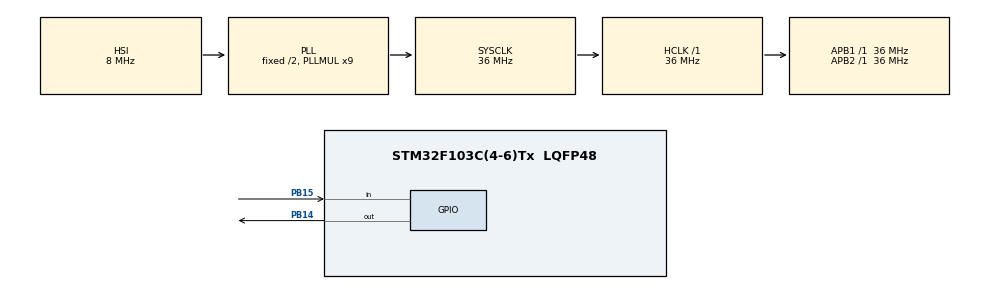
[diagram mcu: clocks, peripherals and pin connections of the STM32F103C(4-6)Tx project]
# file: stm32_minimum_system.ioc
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Mcu.Family=STM32F1
Mcu.Name=STM32F103C(4-6)Tx
Mcu.Package=LQFP48
NVIC.PriorityGroup=NVIC_PRIORITYGROUP_4
PB14.GPIO_PuPd=GPIO_NOPULL
PB14.GPIO_Speed=GPIO_SPEED_FREQ_LOW
PB14.PinState=GPIO_PIN_SET
PB14.Signal=GPIO_Output
PB15.GPIO_PuPd=GPIO_PULLUP
PB15.Signal=GPIO_Input
ProjectManager.HeapSize=0x200
ProjectManager.StackSize=0x400
ProjectManager.TargetToolchain=MDK-ARM V5
RCC.AHBFreq_Value=36000000
RCC.APB1Freq_Value=36000000
RCC.APB1TimFreq_Value=36000000
RCC.APB2Freq_Value=36000000
RCC.APB2TimFreq_Value=36000000
RCC.HCLKFreq_Value=36000000
RCC.PLLMUL=RCC_PLL_MUL9
RCC.SYSCLKFreq_VALUE=36000000
RCC.SYSCLKSource=RCC_SYSCLKSOURCE_PLLCLK
RCC.USBFreq_Value=36000000
VP_SYS_VS_ND.Mode=No_Debug
board=custom

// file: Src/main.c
/* USER CODE BEGIN Header */
/**
  ******************************************************************************
  * @file           : main.c
  * @brief          : Main program body
  ******************************************************************************
  * @attention
  *
  * <h2><center>&copy; Copyright (c) 2019 STMicroelectronics.
  * All rights reserved.</center></h2>
  *
  * This software component is licensed by ST under BSD 3-Clause license,
  * the "License"; You may not use this file except in compliance with the
  * License. You may obtain a copy of the License at:
  *                        opensource.org/licenses/BSD-3-Clause
  *
  ******************************************************************************
  */
/* USER CODE END Header */

#include "main.h"

/* USER CODE BEGIN PD */
#define LED_OFF HAL_GPIO_WritePin(GPIOB, GPIO_PIN_14, GPIO_PIN_SET);  //端口置1
#define LED_ON HAL_GPIO_WritePin(GPIOB, GPIO_PIN_14, GPIO_PIN_RESET);  //端口置0
/* USER CODE END PD */

void SystemClock_Config(void);
static void MX_GPIO_Init(void);

int main(void)
{

  /* MCU Configuration--------------------------------------------------------*/

  /* Reset of all peripherals, Initializes the Flash interface and the Systick. */
  HAL_Init();

  /* Configure the system clock */
  SystemClock_Config();

  /* Initialize all configured peripherals */
  MX_GPIO_Init();

  /* Infinite loop */
  while (1)
  {
    if (HAL_GPIO_ReadPin(GPIOB,GPIO_PIN_15) == 0)
    {
      HAL_Delay(10);  //延迟10ms
      if (HAL_GPIO_ReadPin(GPIOB,GPIO_PIN_15) == 0)
        LED_ON;
    }
    if (HAL_GPIO_ReadPin(GPIOB,GPIO_PIN_15) != 0)
    {
      HAL_Delay(10);  //延迟10ms
      if (HAL_GPIO_ReadPin(GPIOB,GPIO_PIN_15) != 0)
        LED_OFF;
    }
  }
}

void SystemClock_Config(void)
{
  RCC_OscInitTypeDef RCC_OscInitStruct = {0};
  RCC_ClkInitTypeDef RCC_ClkInitStruct = {0};

  /** Initializes the CPU, AHB and APB busses clocks
  */
  RCC_OscInitStruct.OscillatorType = RCC_OSCILLATORTYPE_HSI;
  RCC_OscInitStruct.HSIState = RCC_HSI_ON;
  RCC_OscInitStruct.HSICalibrationValue = RCC_HSICALIBRATION_DEFAULT;
  RCC_OscInitStruct.PLL.PLLState = RCC_PLL_ON;
  RCC_OscInitStruct.PLL.PLLSource = RCC_PLLSOURCE_HSI_DIV2;
  RCC_OscInitStruct.PLL.PLLMUL = RCC_PLL_MUL9;
  if (HAL_RCC_OscConfig(&RCC_OscInitStruct) != HAL_OK)
  {
    Error_Handler();
  }
  /** Initializes the CPU, AHB and APB busses clocks
  */
  RCC_ClkInitStruct.ClockType = RCC_CLOCKTYPE_HCLK|RCC_CLOCKTYPE_SYSCLK
                              |RCC_CLOCKTYPE_PCLK1|RCC_CLOCKTYPE_PCLK2;
  RCC_ClkInitStruct.SYSCLKSource = RCC_SYSCLKSOURCE_PLLCLK;
  RCC_ClkInitStruct.AHBCLKDivider = RCC_SYSCLK_DIV1;
  RCC_ClkInitStruct.APB1CLKDivider = RCC_HCLK_DIV1;
  RCC_ClkInitStruct.APB2CLKDivider = RCC_HCLK_DIV1;

  if (HAL_RCC_ClockConfig(&RCC_ClkInitStruct, FLASH_LATENCY_1) != HAL_OK)
  {
    Error_Handler();
  }
}

static void MX_GPIO_Init(void)
{
  GPIO_InitTypeDef GPIO_InitStruct = {0};  //定义GPIO配置结构体

  /* GPIO Ports Clock Enable */
  __HAL_RCC_GPIOB_CLK_ENABLE();  //使能GPIOB时钟

  /*Configure GPIO pin Output Level */
  HAL_GPIO_WritePin(GPIOB, GPIO_PIN_14, GPIO_PIN_SET);  //配置引脚的初始化电平

  /*Configure GPIO pin : PB14 */
  GPIO_InitStruct.Pin = GPIO_PIN_14;
  GPIO_InitStruct.Mode = GPIO_MODE_OUTPUT_PP;  //设置为推挽输出模式
  GPIO_InitStruct.Pull = GPIO_NOPULL;  //设置既不上拉也不下拉
  GPIO_InitStruct.Speed = GPIO_SPEED_FREQ_LOW;  //输出频率最大为5MHz
  HAL_GPIO_Init(GPIOB, &GPIO_InitStruct);

  /*Configure GPIO pin : PB15 */
  GPIO_InitStruct.Pin = GPIO_PIN_15;
  GPIO_InitStruct.Mode = GPIO_MODE_INPUT;  //设置为输入模式
  GPIO_InitStruct.Pull = GPIO_PULLUP;  //上拉输入
  HAL_GPIO_Init(GPIOB, &GPIO_InitStruct);

}

void Error_Handler(void)
{
}

/************************ (C) COPYRIGHT STMicroelectronics *****END OF FILE****/
